# nrf5002 register map
Vendor: Nordic Semiconductor; Series: nRF50; File version: 1
CPU: CM0 r0p4, little endian, no MPU, no FPU, 2 interrupt priority bits, 32 interrupts
Registers are 32-bit, read-write, reset 0x0 unless marked. A register's access mark holds for its fields unless they carry their own. Offsets are from the block's base; [hi:lo] are bit positions; 'fields as' and 'values as' point back to an identical list.

## CLOCK — Clock management
Base 0x40000000
0x00 TASKS_HFCLKSTART wo — Start HFCLK128M/HFCLK64M source as selected in HFCLKSRC
  [0] TASKS_HFCLKSTART
    1=Trigger task
0x04 TASKS_HFCLKSTOP wo — Stop HFCLK128M/HFCLK64M source
  [0] TASKS_HFCLKSTOP
    1=Trigger task
0x08 TASKS_LFCLKSTART wo — Start LFCLK source as selected in LFCLKSRC
  [0] TASKS_LFCLKSTART
    1=Trigger task
0x0C TASKS_LFCLKSTOP wo — Stop LFCLK source
  [0] TASKS_LFCLKSTOP
    1=Trigger task
0x10 TASKS_CAL wo — Start calibration of LFRC oscillator
  [0] TASKS_CAL
    1=Trigger task
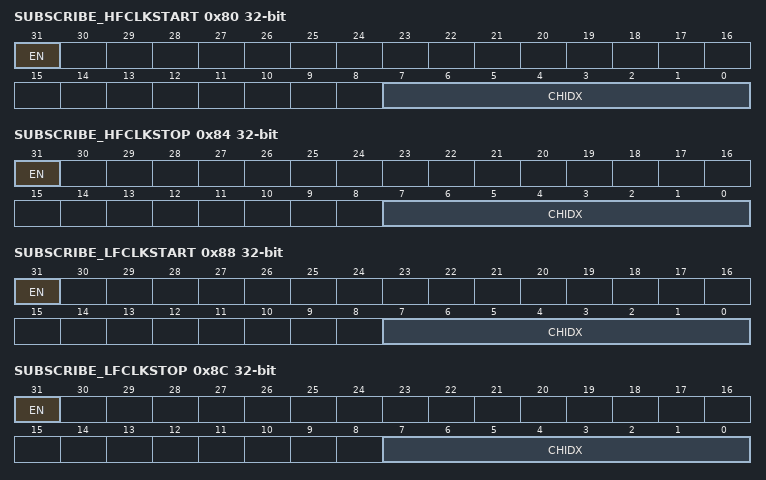
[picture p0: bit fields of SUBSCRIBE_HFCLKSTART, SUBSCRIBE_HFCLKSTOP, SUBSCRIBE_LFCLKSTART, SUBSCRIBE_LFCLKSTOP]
0x80 SUBSCRIBE_HFCLKSTART — Subscribe configuration for task HFCLKSTART
  [31] EN
    0=Disabled (Disable subscription); 1=Enabled (Enable subscription)
  [7:0] CHIDX — DPPI channel that task HFCLKSTART will subscribe to
0x84 SUBSCRIBE_HFCLKSTOP — Subscribe configuration for task HFCLKSTOP
  [31] EN
    values as SUBSCRIBE_HFCLKSTART.EN
  [7:0] CHIDX — DPPI channel that task HFCLKSTOP will subscribe to
0x88 SUBSCRIBE_LFCLKSTART — Subscribe configuration for task LFCLKSTART
  [31] EN
    values as SUBSCRIBE_HFCLKSTART.EN
  [7:0] CHIDX — DPPI channel that task LFCLKSTART will subscribe to
0x8C SUBSCRIBE_LFCLKSTOP — Subscribe configuration for task LFCLKSTOP
  [31] EN
    values as SUBSCRIBE_HFCLKSTART.EN
  [7:0] CHIDX — DPPI channel that task LFCLKSTOP will subscribe to
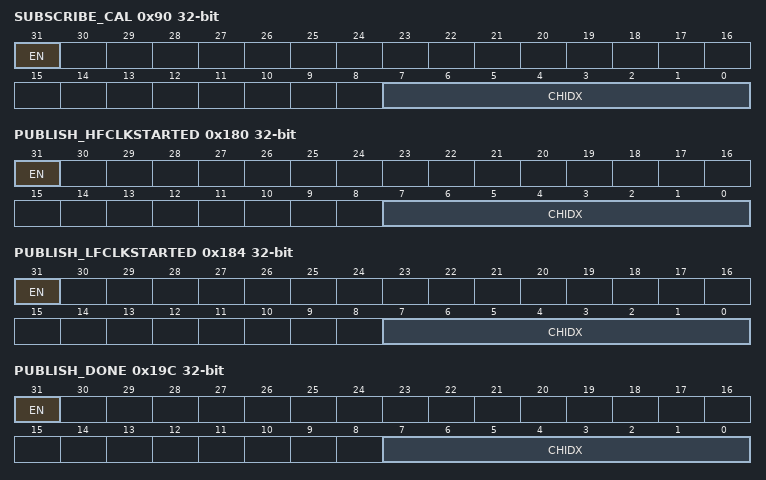
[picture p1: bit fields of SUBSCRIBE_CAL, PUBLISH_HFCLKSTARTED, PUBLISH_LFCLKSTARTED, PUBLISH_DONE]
0x90 SUBSCRIBE_CAL — Subscribe configuration for task CAL
  [31] EN
    values as SUBSCRIBE_HFCLKSTART.EN
  [7:0] CHIDX — DPPI channel that task CAL will subscribe to
0x100 EVENTS_HFCLKSTARTED — HFCLK source started
  [0] EVENTS_HFCLKSTARTED
    0=NotGenerated (Event not generated); 1=Generated (Event generated)
0x104 EVENTS_LFCLKSTARTED — LFCLK source started
  [0] EVENTS_LFCLKSTARTED
    values as EVENTS_HFCLKSTARTED.EVENTS_HFCLKSTARTED
0x11C EVENTS_DONE — Calibration of LFRC oscillator complete event
  [0] EVENTS_DONE
    values as EVENTS_HFCLKSTARTED.EVENTS_HFCLKSTARTED
0x180 PUBLISH_HFCLKSTARTED — Publish configuration for event HFCLKSTARTED
  [31] EN
    0=Disabled (Disable publishing); 1=Enabled (Enable publishing)
  [7:0] CHIDX — DPPI channel that event HFCLKSTARTED will publish to
0x184 PUBLISH_LFCLKSTARTED — Publish configuration for event LFCLKSTARTED
  [31] EN
    values as PUBLISH_HFCLKSTARTED.EN
  [7:0] CHIDX — DPPI channel that event LFCLKSTARTED will publish to
0x19C PUBLISH_DONE — Publish configuration for event DONE
  [31] EN
    values as PUBLISH_HFCLKSTARTED.EN
  [7:0] CHIDX — DPPI channel that event DONE will publish to
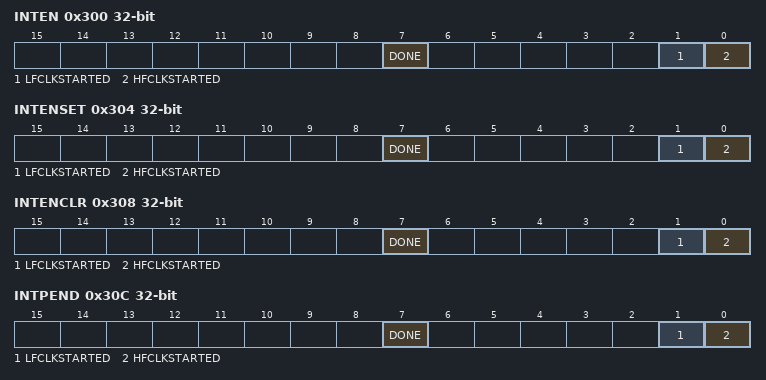
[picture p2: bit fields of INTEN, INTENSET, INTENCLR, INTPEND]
0x300 INTEN — Enable or disable interrupt
  [all] fields
    0=Disabled; 1=Enabled
  [7] DONE — Enable or disable interrupt for event DONE
  [1] LFCLKSTARTED — Enable or disable interrupt for event LFCLKSTARTED
  [0] HFCLKSTARTED — Enable or disable interrupt for event HFCLKSTARTED
0x304 INTENSET — Enable interrupt
  [all] fields
    on read: 0=Disabled (Read: Disabled); 1=Enabled (Read: Enabled) | on write: 1=Set (Enable)
  [7] DONE — Write '1' to enable interrupt for event DONE
  [1] LFCLKSTARTED — Write '1' to enable interrupt for event LFCLKSTARTED
  [0] HFCLKSTARTED — Write '1' to enable interrupt for event HFCLKSTARTED
0x308 INTENCLR — Disable interrupt
  [all] fields
    on read: 0=Disabled (Read: Disabled); 1=Enabled (Read: Enabled) | on write: 1=Clear (Disable)
  [7] DONE — Write '1' to disable interrupt for event DONE
  [1] LFCLKSTARTED — Write '1' to disable interrupt for event LFCLKSTARTED
  [0] HFCLKSTARTED — Write '1' to disable interrupt for event HFCLKSTARTED
0x30C INTPEND ro — Pending interrupts
  [all] fields
    on read: 0=NotPending (Read: Not pending); 1=Pending (Read: Pending)
  [7] DONE — Read pending status of interrupt for event DONE
  [1] LFCLKSTARTED — Read pending status of interrupt for event LFCLKSTARTED
  [0] HFCLKSTARTED — Read pending status of interrupt for event HFCLKSTARTED
0x408 HFCLKRUN ro — Status indicating that HFCLKSTART task has been triggered
  [0] STATUS — HFCLKSTART task triggered or not
    0=NotTriggered (Task not triggered); 1=Triggered (Task triggered)
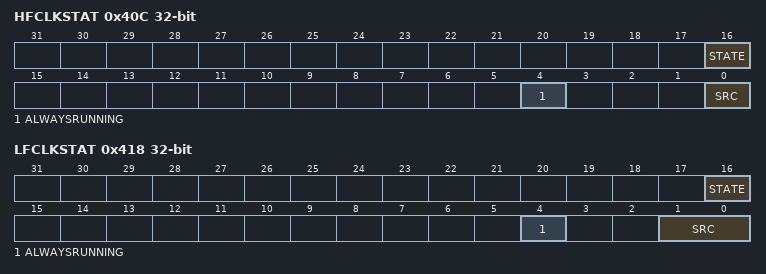
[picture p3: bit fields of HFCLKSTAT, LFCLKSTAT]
0x40C HFCLKSTAT ro — Status indicating which HFCLK128M/HFCLK64M source is running Note: Value of this register in any CLOCK instance reflects status only due to configurations/actions in that CLOCK instance.
  [16] STATE — HFCLK state
    0=NotRunning (HFCLK not running); 1=Running (HFCLK running)
  [4] ALWAYSRUNNING — ALWAYSRUN activated
    0=NotRunning (Automatic clock control enabled); 1=Running (Oscillator is always running)
  [0] SRC — Active clock source
    0=HFINT (Clock source: HFINT - 128 MHz on-chip oscillator); 1=HFXO (Clock source: HFXO - 128 MHz clock derived from external 32 MHz crystal oscillator)
0x414 LFCLKRUN ro — Status indicating that LFCLKSTART task has been triggered
  [0] STATUS — LFCLKSTART task triggered or not
    values as HFCLKRUN.STATUS
0x418 LFCLKSTAT ro — Status indicating which LFCLK source is running Note: Value of this register in any CLOCK instance reflects status only due to configurations/actions in that CLOCK instance.
  [16] STATE — LFCLK state
    0=NotRunning (LFCLK not running); 1=Running (LFCLK running)
  [4] ALWAYSRUNNING — ALWAYSRUN activated
    values as HFCLKSTAT.ALWAYSRUNNING
  [1:0] SRC — Active clock source
    0=LFULP (32.768 kHz ultra-low power RC oscillator); 1=LFRC (32.768 kHz RC oscillator); 2=LFXO (32.768 kHz crystal oscillator); 3=LFSYNT (32.768 kHz synthesized from HFCLK)
0x41C LFCLKSRCCOPY ro reset 0x1 — Copy of LFCLKSRC register, set when LFCLKSTART task was triggered
  [1:0] SRC — Clock source
    values as LFCLKSTAT.SRC
0x430 HFCLKCURRFREQ — Current frequency of HFCLK
  [1:0] HFCLKCURRFREQ — Current high frequency clock (HCLK) frequency
    0=Div1 (HFCLK divided by 1)
0x514 HFCLKSRC reset 0x1 — Clock source for HFCLK
  [0] SRC — Select which HFCLK source is started by the HFCLKSTART task
    0=HFINT (HFCLKSTART task starts HFINT oscillator); 1=HFXO (HFCLKSTART task starts HFXO oscillator)
0x518 LFCLKSRC reset 0x1 — Clock source for LFCLK
  [1:0] SRC — Select which LFCLK source is started by the LFCLKSTART task
    values as LFCLKSTAT.SRC
0x558 HFCLKCTRL — HFCLK frequency configuration
  [1:0] HCLK — High frequency clock HCLK
    0=Div1 (Divide HFCLK by 1)
0x570 HFCLKALWAYSRUN — Automatic or manual control of HFCLK
  [0] ALWAYSRUN — Ensure clock is always running
    0=Automatic (Use automatic clock control); 1=AlwaysRun (Ensure clock is always running)
0x574 LFCLKALWAYSRUN — Automatic or manual control of LFCLK
  fields as HFCLKALWAYSRUN
